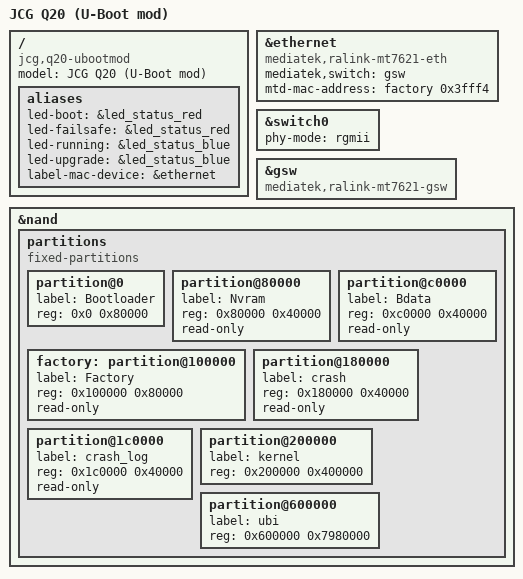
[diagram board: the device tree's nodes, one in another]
// SPDX-License-Identifier: GPL-2.0-or-later OR MIT

#include "mt7621_jcg_nand_128m.dtsi"

/ {
	compatible = "jcg,q20-ubootmod", "mediatek,mt7621-soc";
	model = "JCG Q20 (U-Boot mod)";

	aliases {
		led-boot = &led_status_red;
		led-failsafe = &led_status_red;
		led-running = &led_status_blue;
		led-upgrade = &led_status_blue;
        label-mac-device = &ethernet;
	};
};

&ethernet {
	compatible = "mediatek,ralink-mt7621-eth";
	mediatek,switch = <&gsw>;
	mtd-mac-address = <&factory 0x3fff4>;
};

&switch0 {
	/delete-property/ compatible;
	phy-mode = "rgmii";
};

&gsw {
	compatible = "mediatek,ralink-mt7621-gsw";
};

&nand {
	status = "okay";

	partitions {
		compatible = "fixed-partitions";
		#address-cells = <1>;
		#size-cells = <1>;

		partition@0 {
			label = "Bootloader";
			reg = <0x0 0x80000>;
		};

		partition@80000 {
			label = "Nvram";
			reg = <0x80000 0x40000>;
			read-only;
		};

		partition@c0000 {
			label = "Bdata";
			reg = <0xc0000 0x40000>;
			read-only;
		};

		factory: partition@100000 {
			label = "Factory";
			reg = <0x100000 0x80000>;
			read-only;
		};

		partition@180000 {
			label = "crash";
			reg = <0x180000 0x40000>;
			read-only;
		};

		partition@1c0000 {
			label = "crash_log";
			reg = <0x1c0000 0x40000>;
			read-only;
		};

		partition@200000 {
			label = "kernel";
			reg = <0x200000 0x400000>;
		};

		partition@600000 {
			label = "ubi";
			reg = <0x600000 0x7980000>;
		};
	};
};
